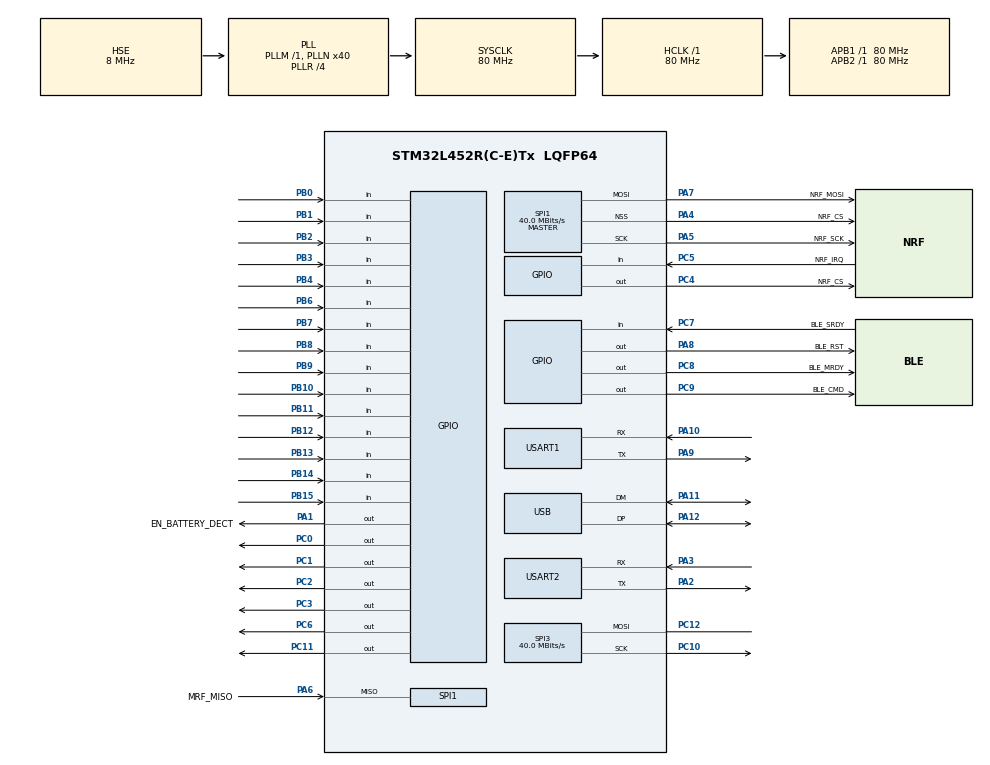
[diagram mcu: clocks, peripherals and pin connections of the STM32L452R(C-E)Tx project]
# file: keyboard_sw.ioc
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Dma.Request0=SPI3_TX
Dma.SPI3_TX.0.Direction=DMA_MEMORY_TO_PERIPH
Dma.SPI3_TX.0.Instance=DMA2_Channel2
Dma.SPI3_TX.0.MemDataAlignment=DMA_MDATAALIGN_BYTE
Dma.SPI3_TX.0.MemInc=DMA_MINC_ENABLE
Dma.SPI3_TX.0.Mode=DMA_NORMAL
Dma.SPI3_TX.0.PeriphDataAlignment=DMA_PDATAALIGN_BYTE
Dma.SPI3_TX.0.PeriphInc=DMA_PINC_DISABLE
Dma.SPI3_TX.0.Priority=DMA_PRIORITY_LOW
FREERTOS.Tasks01=defaultTask,0,128,StartDefaultTask,Default,NULL
Mcu.Family=STM32L4
Mcu.Name=STM32L452R(C-E)Tx
Mcu.Package=LQFP64
NVIC.DMA2_Channel2_IRQn=true\:5\:0\:false\:false\:true\:true\:false\:true
NVIC.PriorityGroup=NVIC_PRIORITYGROUP_4
NVIC.USB_IRQn=true\:5\:0\:false\:false\:true\:true\:false\:true
PA0.GPIO_Label=BATTERY_DECT
PA0.Signal=ADCx_IN5
PA1.GPIO_Label=EN_BATTERY_DECT
PA1.Signal=GPIO_Output
PA10.Mode=Asynchronous
PA10.Signal=USART1_RX
PA11.Mode=Device
PA11.Signal=USB_DM
PA12.Mode=Device
PA12.Signal=USB_DP
PA13\ (JTMS/SWDIO).Mode=Serial_Wire
PA13\ (JTMS/SWDIO).Signal=SYS_JTMS-SWDIO
PA14\ (JTCK/SWCLK).Mode=Serial_Wire
PA14\ (JTCK/SWCLK).Signal=SYS_JTCK-SWCLK
PA2.Mode=Asynchronous
PA2.Signal=USART2_TX
PA3.Mode=Asynchronous
PA3.Signal=USART2_RX
PA4.GPIO_Label=NRF_CS
PA4.Mode=NSS_Signal_Hard_Output
PA4.Signal=SPI1_NSS
PA5.GPIO_Label=NRF_SCK
PA5.Mode=Full_Duplex_Master
PA5.Signal=SPI1_SCK
PA6.GPIO_Label=MRF_MISO
PA6.Mode=Full_Duplex_Master
PA6.Signal=SPI1_MISO
PA7.GPIO_Label=NRF_MOSI
PA7.Mode=Full_Duplex_Master
PA7.Signal=SPI1_MOSI
PA8.GPIO_Label=BLE_RST
PA8.Signal=GPIO_Output
PA9.Mode=Asynchronous
PA9.Signal=USART1_TX
PB0.Signal=GPIO_Input
PB1.Signal=GPIO_Input
PB10.Signal=GPIO_Input
PB11.Signal=GPIO_Input
PB12.Signal=GPIO_Input
PB13.Signal=GPIO_Input
PB14.Signal=GPIO_Input
PB15.Signal=GPIO_Input
PB2.Signal=GPIO_Input
PB3\ (JTDO/TRACESWO).Signal=GPIO_Input
PB4\ (NJTRST).Signal=GPIO_Input
PB6.Signal=GPIO_Input
PB7.Signal=GPIO_Input
PB8.Signal=GPIO_Input
PB9.Signal=GPIO_Input
PC0.Signal=GPIO_Output
PC1.Signal=GPIO_Output
PC10.Mode=Simplex_Bidirectional_Master
PC10.Signal=SPI3_SCK
PC11.Signal=GPIO_Output
PC12.Mode=Simplex_Bidirectional_Master
PC12.Signal=SPI3_MOSI
PC2.Signal=GPIO_Output
PC3.Signal=GPIO_Output
PC4.GPIO_Label=NRF_CS
PC4.Signal=GPIO_Output
PC5.GPIO_Label=NRF_IRQ
PC5.Signal=GPIO_Input
PC6.Signal=GPIO_Output
PC7.GPIO_Label=BLE_SRDY
PC7.Signal=GPIO_Input
PC8.GPIO_Label=BLE_MRDY
PC8.Signal=GPIO_Output
PC9.GPIO_Label=BLE_CMD
PC9.Signal=GPIO_Output
PH0-OSC_IN\ (PH0).Mode=HSE-External-Oscillator
PH0-OSC_IN\ (PH0).Signal=RCC_OSC_IN
PH1-OSC_OUT\ (PH1).Mode=HSE-External-Oscillator
PH1-OSC_OUT\ (PH1).Signal=RCC_OSC_OUT
ProjectManager.HeapSize=0x200
ProjectManager.StackSize=0x400
ProjectManager.TargetToolchain=EWARM V8
RCC.ADCFreq_Value=48000000
RCC.AHBFreq_Value=80000000
RCC.APB1Freq_Value=80000000
RCC.APB1TimFreq_Value=80000000
RCC.APB2Freq_Value=80000000
RCC.APB2TimFreq_Value=80000000
RCC.CortexFreq_Value=80000000
RCC.HCLKFreq_Value=80000000
RCC.HSE_VALUE=8000000
RCC.HSI48_VALUE=48000000
RCC.HSI_VALUE=16000000
RCC.LSE_VALUE=32768
RCC.MSI_VALUE=4000000
RCC.PLLN=40
RCC.PLLR=RCC_PLLR_DIV4
RCC.PLLSAI1N=12
RCC.PLLSourceVirtual=RCC_PLLSOURCE_HSE
RCC.SYSCLKFreq_VALUE=80000000
RCC.SYSCLKSource=RCC_SYSCLKSOURCE_PLLCLK
RCC.USBFreq_Value=48000000
RCC.VCOOutputFreq_Value=320000000
SH.ADCx_IN5.0=ADC1_IN5
SPI1.BaudRatePrescaler=SPI_BAUDRATEPRESCALER_2
SPI1.CalculateBaudRate=40.0 MBits/s
SPI1.Direction=SPI_DIRECTION_2LINES
SPI1.Mode=SPI_MODE_MASTER
SPI1.VirtualNSS=VM_NSSHARD
SPI1.VirtualType=VM_MASTER
SPI3.CalculateBaudRate=40.0 MBits/s
SPI3.Direction=SPI_DIRECTION_1LINE
SPI3.Mode=SPI_MODE_MASTER
SPI3.VirtualType=VM_MASTER
USART1.VirtualMode-Asynchronous=VM_ASYNC
USART2.VirtualMode-Asynchronous=VM_ASYNC
USB_DEVICE.CLASS_NAME_FS=HID
USB_DEVICE.VirtualMode=Hid
USB_DEVICE.VirtualModeFS=Hid_FS
VP_FATFS_VS_Generic.Mode=User_defined
VP_FREERTOS_VS_CMSIS_V1.Mode=CMSIS_V1
VP_USB_DEVICE_VS_USB_DEVICE_HID_FS.Mode=HID_FS
VP_WWDG_VS_WWDG.Mode=WWDG_Activate
board=custom

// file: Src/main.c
/* USER CODE BEGIN Header */
/**
  ******************************************************************************
  * @file           : main.c
  * @brief          : Main program body
  ******************************************************************************
  * @attention
  *
  * <h2><center>&copy; Copyright (c) 2019 STMicroelectronics.
  * All rights reserved.</center></h2>
  *
  * This software component is licensed by ST under Ultimate Liberty license
  * SLA0044, the "License"; You may not use this file except in compliance with
  * the License. You may obtain a copy of the License at:
  *                             www.st.com/SLA0044
  *
  ******************************************************************************
  */
/* USER CODE END Header */

#include "main.h"
#include "cmsis_os.h"
#include "fatfs.h"
#include "spi.h"
#include "usart.h"
#include "usb_device.h"
#include "wwdg.h"
#include "gpio.h"

/* USER CODE BEGIN Includes */
#include "dma.h"
#include "ws2812b.h"
#include "usb_device.h"
#include "usbd_core.h"
#include "usbd_desc.h"
#include "usbd_hid.h"
extern USBD_HandleTypeDef hUsbDeviceFS;
/* USER CODE END Includes */

void SystemClock_Config(void);
void MX_FREERTOS_Init(void);

int main(void)
{

	/* MCU Configuration--------------------------------------------------------*/

	/* Reset of all peripherals, Initializes the Flash interface and the Systick. */
	HAL_Init();

	/* Configure the system clock */
	SystemClock_Config();

	/* Initialize all configured peripherals */
	MX_GPIO_Init();
	MX_DMA_Init();
	MX_SPI1_Init();
	MX_SPI3_Init();
	MX_USART1_UART_Init();
	MX_USART2_UART_Init();
	//MX_WWDG_Init();
	/* USER CODE BEGIN 2 */
	WS2812B_Init();
	WS2812B_Test();
	/* USER CODE END 2 */

	/* Call init function for freertos objects (in freertos.c) */
	MX_FREERTOS_Init();

	/* Start scheduler */
	osKernelStart();

	/* We should never get here as control is now taken by the scheduler */

	/* Infinite loop */
	/* USER CODE BEGIN WHILE */
	while (1)
	{
		//uint8_t txbuffer[8] = {0x00, 0x00, 0x00, 0x00, 0x00, 0x00, 0x00, 0x00}; //�?

		//uint8_t sendbuffer[8] = {0x00, 0x00, 0x1E, 0x00, 0x00, 0x00, 0x00, 0x00}; //空格

		/* USER CODE END WHILE */

	}
}

void SystemClock_Config(void)
{
	RCC_OscInitTypeDef RCC_OscInitStruct = {0};
	RCC_ClkInitTypeDef RCC_ClkInitStruct = {0};
	RCC_PeriphCLKInitTypeDef PeriphClkInit = {0};

	/** Initializes the CPU, AHB and APB busses clocks
  */
	RCC_OscInitStruct.OscillatorType = RCC_OSCILLATORTYPE_HSE;
	RCC_OscInitStruct.HSEState = RCC_HSE_ON;
	RCC_OscInitStruct.PLL.PLLState = RCC_PLL_ON;
	RCC_OscInitStruct.PLL.PLLSource = RCC_PLLSOURCE_HSE;
	RCC_OscInitStruct.PLL.PLLM = 1;
	RCC_OscInitStruct.PLL.PLLN = 40;
	RCC_OscInitStruct.PLL.PLLP = RCC_PLLP_DIV7;
	RCC_OscInitStruct.PLL.PLLQ = RCC_PLLQ_DIV2;
	RCC_OscInitStruct.PLL.PLLR = RCC_PLLR_DIV4;
	if (HAL_RCC_OscConfig(&RCC_OscInitStruct) != HAL_OK)
	{
		Error_Handler();
	}
	/** Initializes the CPU, AHB and APB busses clocks
  */
	RCC_ClkInitStruct.ClockType = RCC_CLOCKTYPE_HCLK | RCC_CLOCKTYPE_SYSCLK | RCC_CLOCKTYPE_PCLK1 | RCC_CLOCKTYPE_PCLK2;
	RCC_ClkInitStruct.SYSCLKSource = RCC_SYSCLKSOURCE_PLLCLK;
	RCC_ClkInitStruct.AHBCLKDivider = RCC_SYSCLK_DIV1;
	RCC_ClkInitStruct.APB1CLKDivider = RCC_HCLK_DIV1;
	RCC_ClkInitStruct.APB2CLKDivider = RCC_HCLK_DIV1;

	if (HAL_RCC_ClockConfig(&RCC_ClkInitStruct, FLASH_LATENCY_4) != HAL_OK)
	{
		Error_Handler();
	}
	PeriphClkInit.PeriphClockSelection = RCC_PERIPHCLK_USART1 | RCC_PERIPHCLK_USART2 | RCC_PERIPHCLK_USB;
	PeriphClkInit.Usart1ClockSelection = RCC_USART1CLKSOURCE_PCLK2;
	PeriphClkInit.Usart2ClockSelection = RCC_USART2CLKSOURCE_PCLK1;
	PeriphClkInit.UsbClockSelection = RCC_USBCLKSOURCE_PLLSAI1;
	PeriphClkInit.PLLSAI1.PLLSAI1Source = RCC_PLLSOURCE_HSE;
	PeriphClkInit.PLLSAI1.PLLSAI1M = 1;
	PeriphClkInit.PLLSAI1.PLLSAI1N = 12;
	PeriphClkInit.PLLSAI1.PLLSAI1P = RCC_PLLP_DIV7;
	PeriphClkInit.PLLSAI1.PLLSAI1Q = RCC_PLLQ_DIV2;
	PeriphClkInit.PLLSAI1.PLLSAI1R = RCC_PLLR_DIV2;
	PeriphClkInit.PLLSAI1.PLLSAI1ClockOut = RCC_PLLSAI1_48M2CLK;
	if (HAL_RCCEx_PeriphCLKConfig(&PeriphClkInit) != HAL_OK)
	{
		Error_Handler();
	}
	/** Configure the main internal regulator output voltage
  */
	if (HAL_PWREx_ControlVoltageScaling(PWR_REGULATOR_VOLTAGE_SCALE1) != HAL_OK)
	{
		Error_Handler();
	}
}

void Error_Handler(void)
{
}

/************************ (C) COPYRIGHT STMicroelectronics *****END OF FILE****/

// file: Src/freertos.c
/* USER CODE BEGIN Header */
/**
  ******************************************************************************
  * File Name          : freertos.c
  * Description        : Code for freertos applications
  ******************************************************************************
  * @attention
  *
  * <h2><center>&copy; Copyright (c) 2019 STMicroelectronics.
  * All rights reserved.</center></h2>
  *
  * This software component is licensed by ST under Ultimate Liberty license
  * SLA0044, the "License"; You may not use this file except in compliance with
  * the License. You may obtain a copy of the License at:
  *                             www.st.com/SLA0044
  *
  ******************************************************************************
  */
/* USER CODE END Header */

#include "FreeRTOS.h"
#include "task.h"
#include "main.h"
#include "cmsis_os.h"

osThreadId defaultTaskHandle;

void StartDefaultTask(void const * argument);

extern void MX_USB_DEVICE_Init(void);
extern void MX_FATFS_Init(void);
void MX_FREERTOS_Init(void); /* (MISRA C 2004 rule 8.1) */

void MX_FREERTOS_Init(void) {

  /* Create the thread(s) */
  /* definition and creation of defaultTask */
  osThreadDef(defaultTask, StartDefaultTask, osPriorityNormal, 0, 128*10);
  defaultTaskHandle = osThreadCreate(osThread(defaultTask), NULL);

}

void StartDefaultTask(void const * argument)
{
  /* init code for USB_DEVICE */
  MX_USB_DEVICE_Init();

  /* init code for FATFS */
  MX_FATFS_Init();

  for(;;)
  {
    osDelay(1);
  }
}

/************************ (C) COPYRIGHT STMicroelectronics *****END OF FILE****/
